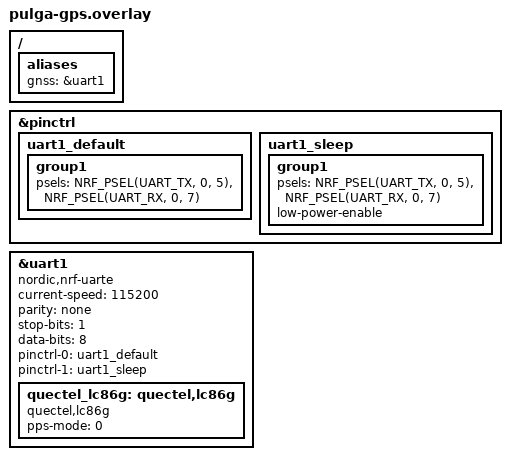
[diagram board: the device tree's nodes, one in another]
/*
 * Copyright (c) 2024 LSI-TEC
 *
 * SPDX-License-Identifier: Apache-2.0
 */

/ {
	aliases {
		gnss = &uart1;
	};
};

&pinctrl {
	uart1_default: uart1_default {
		group1 {
			psels = <NRF_PSEL(UART_TX, 0, 5)>,
			        <NRF_PSEL(UART_RX, 0, 7)>;
		};
	};

	uart1_sleep: uart1_sleep {
		group1 {
			psels = <NRF_PSEL(UART_TX, 0, 5)>,
			        <NRF_PSEL(UART_RX, 0, 7)>;
			low-power-enable;
		};
	};
};


&uart1 {
	compatible = "nordic,nrf-uarte";
	status = "okay";
	
	current-speed = <115200>;
	parity = "none";
	stop-bits = "1";
	data-bits = <8>;
	
	pinctrl-0 = <&uart1_default>;
	pinctrl-1 = <&uart1_sleep>;
	pinctrl-names = "default", "sleep";
	
	// Compatible with L86
	quectel_lc86g: quectel,lc86g {
		status = "okay";
		compatible = "quectel,lc86g";
		// GNSS_PPS_MODE_DISABLED
		pps-mode = <0>;
	};
};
